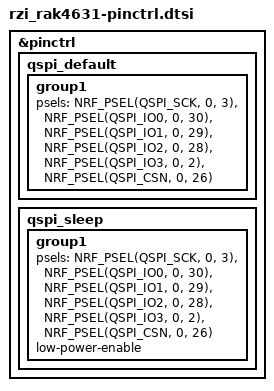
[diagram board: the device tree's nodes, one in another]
/*
 * Copyright (c) 2022 Nordic Semiconductor
 * SPDX-License-Identifier: Apache-2.0
 *
 * QSPI pinout of the RAK4631 WisBlock core. The module pads (UART, I2C,
 * and the SX1262 SPI) are in rzi_rak4630.dtsi.
 */

&pinctrl {
	qspi_default: qspi_default {
		group1 {
			psels = <NRF_PSEL(QSPI_SCK, 0, 3)>,
				<NRF_PSEL(QSPI_IO0, 0, 30)>,
				<NRF_PSEL(QSPI_IO1, 0, 29)>,
				<NRF_PSEL(QSPI_IO2, 0, 28)>,
				<NRF_PSEL(QSPI_IO3, 0, 2)>,
				<NRF_PSEL(QSPI_CSN, 0, 26)>;
		};
	};

	qspi_sleep: qspi_sleep {
		group1 {
			psels = <NRF_PSEL(QSPI_SCK, 0, 3)>,
				<NRF_PSEL(QSPI_IO0, 0, 30)>,
				<NRF_PSEL(QSPI_IO1, 0, 29)>,
				<NRF_PSEL(QSPI_IO2, 0, 28)>,
				<NRF_PSEL(QSPI_IO3, 0, 2)>,
				<NRF_PSEL(QSPI_CSN, 0, 26)>;
			low-power-enable;
		};
	};
};
